# M411_unitB register map
File version: 2.0.2.2
Registers are 32-bit, read-write, no defined reset value unless marked. A register's access mark holds for its fields unless they carry their own. Offsets are from the block's base; [hi:lo] are bit positions; {n}, {i} and the like mark numbered series.

## AES — Advanced Encryption Standard (AES)
Base 0x400B8200
0x00 DT wo reset 0x0 — Plaintext_encrypted text data Register
0x04 KEY7 reset 0x0 — Input Key Data Register (bit 31 - 0)
  [31:0] KEY
0x08 KEY6 reset 0x0 — Input Key Data Register (bit 63 - 32)
  [31:0] KEY
0x0C KEY5 reset 0x0 — Input Key Data Register (bit 95 - 64)
  [31:0] KEY
0x10 KEY4 reset 0x0 — Input Key Data Register (bit 127 - 96)
  [31:0] KEY
0x14 KEY3 reset 0x0 — Input Key Data Register (bit 159 - 128)
  [31:0] KEY
0x18 KEY2 reset 0x0 — Input Key Data Register (bit 191 - 160)
  [31:0] KEY
0x1C KEY1 reset 0x0 — Input Key Data Register (bit 223 - 192)
  [31:0] KEY
0x20 KEY0 reset 0x0 — Input Key Data Register (bit 255 - 224)
  [31:0] KEY
0x24 CNT3 reset 0x0 — Counter Initial Value Register (bit 31 - 0)
  [31:0] CNT
0x28 CNT2 reset 0x0 — Counter Initial Value Register (bit 63 - 32)
  [31:0] CNT
0x2C CNT1 reset 0x0 — Counter Initial Value Register (bit 95 - 64)
  [31:0] CNT
0x30 CNT0 reset 0x0 — Counter Initial Value Register (bit 127 - 96)
  [31:0] CNT
0x34 IV3 reset 0x0 — Initial Vector Register (bit 31 - 0)
  [31:0] IV
0x38 IV2 reset 0x0 — Initial Vector Register (bit 63 - 32)
  [31:0] IV
0x3C IV1 reset 0x0 — Initial Vector Register (bit 95 - 64)
  [31:0] IV
0x40 IV0 reset 0x0 — Initial Vector Register (bit 127 - 96)
  [31:0] IV
0x44 ODT ro reset 0x0 — Calculation Result Store Register
0x48 RKEY7 ro reset 0x0 — Output Key Store Register (bit 31 - 0)
  [31:0] RKEY
0x4C RKEY6 ro reset 0x0 — Output Key Store Register (bit 63 - 32)
  [31:0] RKEY
0x50 RKEY5 ro reset 0x0 — Output Key Store Register (bit 95 - 64)
  [31:0] RKEY
0x54 RKEY4 ro reset 0x0 — Output Key Store Register (bit 127 - 96)
  [31:0] RKEY
0x58 RKEY3 ro reset 0x0 — Output Key Store Register (bit 159 - 128)
  [31:0] RKEY
0x5C RKEY2 ro reset 0x0 — Output Key Store Register (bit 191 - 160)
  [31:0] RKEY
0x60 RKEY1 ro reset 0x0 — Output Key Store Register (bit 223 - 192)
  [31:0] RKEY
0x64 RKEY0 ro reset 0x0 — Output Key Store Register (bit 255 - 224)
  [31:0] RKEY
0x68 CLR wo reset 0x0 — FIFO Clear Register
  [0] FIFOCLR
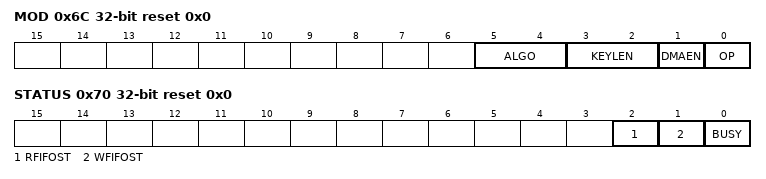
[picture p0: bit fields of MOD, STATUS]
0x6C MOD reset 0x0 — Mode Setting Register
  [5:4] ALGO, [3:2] KEYLEN, [1] DMAEN, [0] OP
0x70 STATUS ro reset 0x0
  [2] RFIFOST, [1] WFIFOST, [0] BUSY

## SHA — Secure Hash Algorithm Processor (SHA)
Base 0x400B8300
0x00 START wo reset 0x0 — Process Start Register
  [0] START
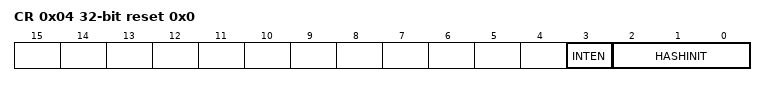
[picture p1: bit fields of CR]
0x04 CR reset 0x0 — Control Register
  [3] INTEN, [2:0] HASHINIT
0x08 DMAEN reset 0x0 — DMA Enable Register
  [0] DMAEN
0x0C MSGLEN0 reset 0x0 — Whole Message Length Register (bit 31 - 0)
  [31:0] LEN
0x10 MSGLEN1 reset 0x0 — Whole Message Length Register (bit 60 - 32)
  [28:0] LEN
0x14 REMAIN0 reset 0x0 — Unhandled Message Length Register (bit 31 - 0)
  [31:0] REMAIN
0x18 REMAIN1 reset 0x0 — Unhandled Message Length Register (bit 60 - 32)
  [28:0] REMAIN
{0x1C+4i} MSG{i:02} reset 0x0 (i=0..15) — Message Register (bit {32i+31} - {32i})
  [31:0] MSG
{0x5C+4i} INIT{i} reset 0x0 (i=0..7) — Hash Initial Value Register (bit {32i+31} - {32i})
  [31:0] INIT
{0x7C+4i} RESULT{i} ro reset 0x0 (i=0..7) — Calculation Result Register (bit {32i+31} - {32i})
  [31:0] RESULT
0x9C STATUS ro reset 0x0
  [0] BUSY

## ESG — Entropy Seed Generator (ESG)
Base 0x400B8400
0x00 CR wo reset 0x0 — Control Register
  [0] START
0x04 ST ro reset 0x0 — Status Register
  [0] BUSY
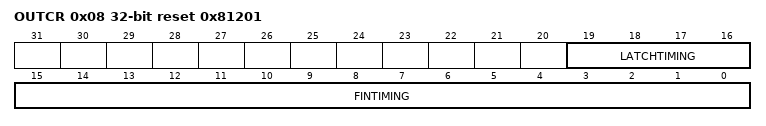
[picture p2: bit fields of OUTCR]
0x08 OUTCR reset 0x81201 — Output Control Register
  [19:16] LATCHTIMING, [15:0] FINTIMING
0x0C INT reset 0x0 — Interrupt Status Register
  [0] INT
{0x10+4i} BLK{i:02} ro reset 0x0 (i=0..15) — Entropy Seed Store Block {i:02}
  [31:0] BLK

## MLA — Multiple Length Arithmetic Coprocessor (MLA)
Base 0x400B9000
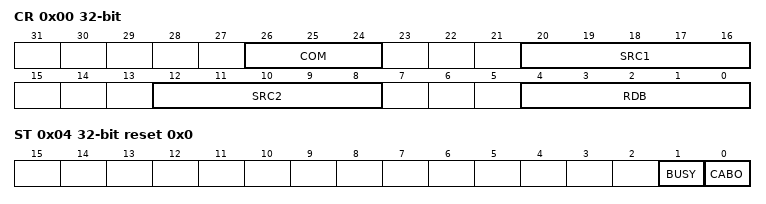
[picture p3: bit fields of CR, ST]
0x00 CR — Control Register
  [26:24] COM, [20:16] SRC1, [12:8] SRC2, [4:0] RDB
0x04 ST reset 0x0 — Status Register
  [1] BUSY, [0] CABO
0x0C PARA — Montgomery Parameter Register
{0x10+4i} BLK1_{i} (i=0..7) — General-purpose Register Block 1 (bit {32i+31} - {32i})
  [31:0] BLK
{0x30+4i} BLK2_{i} (i=0..7) — General-purpose Register Block 2 (bit {32i+31} - {32i})
  [31:0] BLK
{0x50+4i} BLK3_{i} (i=0..7) — General-purpose Register Block 3 (bit {32i+31} - {32i})
  [31:0] BLK
{0x70+4i} BLK4_{i} (i=0..7) — General-purpose Register Block 4 (bit {32i+31} - {32i})
  [31:0] BLK
{0x90+4i} BLK5_{i} (i=0..7) — General-purpose Register Block 5 (bit {32i+31} - {32i})
  [31:0] BLK
{0xB0+4i} BLK6_{i} (i=0..7) — General-purpose Register Block 6 (bit {32i+31} - {32i})
  [31:0] BLK
{0xD0+4i} BLK7_{i} (i=0..7) — General-purpose Register Block 7 (bit {32i+31} - {32i})
  [31:0] BLK
{0xF0+4i} BLK8_{i} (i=0..7) — General-purpose Register Block 8 (bit {32i+31} - {32i})
  [31:0] BLK
{0x110+4i} BLK9_{i} (i=0..7) — General-purpose Register Block 9 (bit {32i+31} - {32i})
  [31:0] BLK
{0x130+4i} BLK10_{i} (i=0..7) — General-purpose Register Block 10 (bit {32i+31} - {32i})
  [31:0] BLK
{0x150+4i} BLK11_{i} (i=0..7) — General-purpose Register Block 11 (bit {32i+31} - {32i})
  [31:0] BLK
{0x170+4i} BLK12_{i} (i=0..7) — General-purpose Register Block 12 (bit {32i+31} - {32i})
  [31:0] BLK
{0x190+4i} BLK13_{i} (i=0..7) — General-purpose Register Block 13 (bit {32i+31} - {32i})
  [31:0] BLK
{0x1B0+4i} BLK14_{i} (i=0..7) — General-purpose Register Block 14 (bit {32i+31} - {32i})
  [31:0] BLK
{0x1D0+4i} BLK15_{i} (i=0..7) — General-purpose Register Block 15 (bit {32i+31} - {32i})
  [31:0] BLK
{0x1F0+4i} BLK16_{i} (i=0..7) — General-purpose Register Block 16 (bit {32i+31} - {32i})
  [31:0] BLK
{0x210+4i} BLK17_{i} (i=0..7) — General-purpose Register Block 17 (bit {32i+31} - {32i})
  [31:0] BLK
{0x230+4i} BLK18_{i} (i=0..7) — General-purpose Register Block 18 (bit {32i+31} - {32i})
  [31:0] BLK
{0x250+4i} BLK19_{i} (i=0..7) — General-purpose Register Block 19 (bit {32i+31} - {32i})
  [31:0] BLK
{0x270+4i} BLK20_{i} (i=0..7) — General-purpose Register Block 20 (bit {32i+31} - {32i})
  [31:0] BLK
{0x290+4i} BLK21_{i} (i=0..7) — General-purpose Register Block 21 (bit {32i+31} - {32i})
  [31:0] BLK
{0x2B0+4i} BLK22_{i} (i=0..7) — General-purpose Register Block 22 (bit {32i+31} - {32i})
  [31:0] BLK
{0x2D0+4i} BLK23_{i} (i=0..7) — General-purpose Register Block 23 (bit {32i+31} - {32i})
  [31:0] BLK
{0x2F0+4i} BLK24_{i} (i=0..7) — General-purpose Register Block 24 (bit {32i+31} - {32i})
  [31:0] BLK
{0x310+4i} BLK25_{i} (i=0..7) — General-purpose Register Block 25 (bit {32i+31} - {32i})
  [31:0] BLK
{0x330+4i} BLK26_{i} (i=0..7) — General-purpose Register Block 26 (bit {32i+31} - {32i})
  [31:0] BLK
{0x350+4i} BLK27_{i} (i=0..7) — General-purpose Register Block 27 (bit {32i+31} - {32i})
  [31:0] BLK
{0x370+4i} BLK28_{i} (i=0..7) — General-purpose Register Block 28 (bit {32i+31} - {32i})
  [31:0] BLK
{0x390+4i} BLK29_{i} (i=0..7) — General-purpose Register Block 29 (bit {32i+31} - {32i})
  [31:0] BLK
{0x3B0+4i} BLK30_{i} (i=0..7) — General-purpose Register Block 30 (bit {32i+31} - {32i})
  [31:0] BLK
{0x3D0+4i} BLK31_{i} (i=0..7) — General-purpose Register Block 31 (bit {32i+31} - {32i})
  [31:0] BLK
{0x800+4i} BLK0_{i} (i=0..7) — General-purpose Register Block 0 (bit {32i+31} - {32i})
  [31:0] BLK
